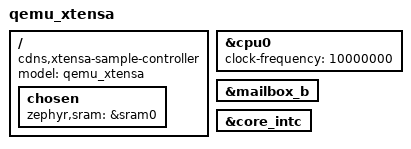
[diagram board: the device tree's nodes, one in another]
/*
 * Copyright (c) 2019 Intel Corporation.
 *
 * SPDX-License-Identifier: Apache-2.0
 */

/dts-v1/;

#include "nxp/nxp_rt5xx_dsp.dtsi"

/ {
	model = "qemu_xtensa";
	compatible = "cdns,xtensa-sample-controller";

	chosen {
		zephyr,sram = &sram0;
	};
};

&cpu0 {
	clock-frequency = <10000000>;
};

&mailbox_b {
	status = "okay";
};

&core_intc {
	status = "okay";
};
